# ATtiny1617 register map
Vendor: Atmel; File version: 1.0
CPU: other r0p0, little endian, no MPU, no FPU, 4 interrupt priority bits
Registers are 8-bit, read-write, reset 0x0 unless marked. A register's access mark holds for its fields unless they carry their own. Offsets are from the block's base; lines under a group give offsets from that group; [hi:lo] are bit positions; {n}, {i} and the like mark numbered series; 'fields as' and 'values as' point back to an identical list; <NAME> marks a mode.

## Memory map
0x00800000 VPORTA size 0x4 — Virtual Ports
0x00800004 VPORTB size 0x4 — Virtual Ports
0x00800008 VPORTC size 0x4 — Virtual Ports
0x0080001C GPIO size 0x4 — General Purpose IO
0x00800034 CPU blocks up to offset 0xB
0x00800040 RSTCTRL size 0x2 — Reset controller
0x00800050 SLPCTRL size 0x1 — Sleep Controller
0x00800060 CLKCTRL blocks up to offset 0x1D — Clock controller
0x00800080 BOD blocks up to offset 0xC — Bod interface
0x008000A0 VREF size 0x4 — Voltage reference
0x00800100 WDT size 0x2 — Watch-Dog Timer
0x00800110 CPUINT size 0x4 — Interrupt Controller
0x00800120 CRCSCAN size 0x3
0x00800140 RTC blocks up to offset 0x16 — Real-Time Counter
0x00800180 EVSYS blocks up to offset 0x24 — Event System
0x008001C0 CCL blocks up to offset 0xD — Configurable Custom Logic
0x00800200 PORTMUX size 0x4 — Port Multiplexer
0x00800400 PORTA blocks up to offset 0x18 — I/O Ports
0x00800420 PORTB blocks up to offset 0x18 — I/O Ports
0x00800440 PORTC blocks up to offset 0x18 — I/O Ports
0x00800600 ADC0 blocks up to offset 0x17 — Analog to Digital Converter
0x00800640 ADC1 blocks up to offset 0x17 — Analog to Digital Converter
0x00800680 AC0 blocks up to offset 0x8 — Analog Comparator
0x00800688 AC1 blocks up to offset 0x8 — Analog Comparator
0x00800690 AC2 blocks up to offset 0x8 — Analog Comparator
0x008006A0 DAC0 size 0x2 — Digital to Analog Converter
0x008006A8 DAC1 size 0x2 — Digital to Analog Converter
0x008006B0 DAC2 size 0x2 — Digital to Analog Converter
0x00800800 USART0 blocks up to offset 0xF — Universal Synchronous and Asynchronous Receiver and Transmitter
0x00800810 TWI0 blocks up to offset 0xF — Two-Wire Interface
0x00800820 SPI0 size 0x5 — Serial Peripheral Interface
0x00800A00 TCA0 blocks up to offset 0x3E — 16-bit Timer/Counter Type A
0x00800A40 TCB0 blocks up to offset 0xE — 16-bit Timer Type B
0x00800A50 TCB1 blocks up to offset 0xE — 16-bit Timer Type B
0x00800A80 TCD0 blocks up to offset 0x30 — Timer Counter D
0x00800F01 SYSCFG size 0x2 — System Configuration Registers
0x00801000 NVMCTRL blocks up to offset 0xA — Non-volatile Memory Controller
0x00801100 SIGROW blocks up to offset 0x26 — Signature row
0x00801280 FUSE blocks up to offset 0x9 — Fuses
0x0080128A LOCKBIT size 0x1
0x00801300 USERROW size 0x20

## Interrupts
1 CRCSCAN_NMI (CPU)
2 BOD_VLM (CPU)
3 PORTA_PORT (CPU)
4 PORTB_PORT (CPU)
5 PORTC_PORT (CPU)
6 RTC_CNT (CPU)
7 RTC_PIT (CPU)
8 TCA0_LUNF_OVF (CPU)
9 TCA0_HUNF (CPU)
10 TCA0_CMP0_LCMP0 (CPU)
11 TCA0_CMP1_LCMP1 (CPU)
12 TCA0_CMP2_LCMP2 (CPU)
13 TCB0_INT (CPU)
14 TCB1_INT (CPU)
15 TCD0_OVF (CPU)
16 TCD0_TRIG (CPU)
17 AC0_AC (CPU)
18 AC1_AC (CPU)
19 AC2_AC (CPU)
20 ADC0_RESRDY (CPU)
21 ADC0_WCOMP (CPU)
22 ADC1_RESRDY (CPU)
23 ADC1_WCOMP (CPU)
24 TWI0_TWIS (CPU)
25 TWI0_TWIM (CPU)
26 SPI0_INT (CPU)
27 USART0_RXC (CPU)
28 USART0_DRE (CPU)
29 USART0_TXC (CPU)
30 NVMCTRL_EE (CPU)

## AC0 — Analog Comparator
Base 0x00800680
Same registers: AC1 0x00800688, AC2 0x00800690
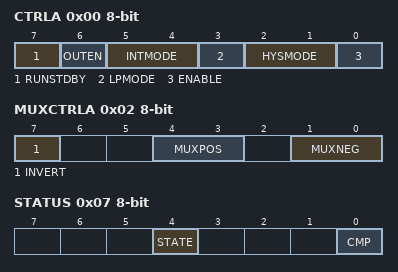
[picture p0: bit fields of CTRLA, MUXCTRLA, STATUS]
0x00 CTRLA — Control A
  [7] RUNSTDBY — Run in Standby Mode
  [6] OUTEN — Output Buffer Enable
  [5:4] INTMODE — Interrupt Mode
    0=BOTHEDGE (Any Edge); 2=NEGEDGE (Negative Edge); 3=POSEDGE (Positive Edge)
  [3] LPMODE — Low Power Mode
    0=DIS (Low power mode disabled); 1=EN (Low power mode enabled)
  [2:1] HYSMODE — Hysteresis Mode
    0=OFF (No hysteresis); 1=10mV hysteresis; 2=25mV hysteresis; 3=50mV hysteresis
  [0] ENABLE
0x02 MUXCTRLA — Mux Control A
  [7] INVERT — Invert AC Output
  [4:3] MUXPOS — Positive Input MUX Selection
    {v}=PIN{v} (Positive Pin {v}) (v=0..3)
  [1:0] MUXNEG — Negative Input MUX Selection
    0=PIN0 (Negative Pin 0); 1=PIN1 (Negative Pin 1); 2=VREF (Voltage Reference); 3=DAC (DAC output)
0x06 INTCTRL — Interrupt Control
  [0] CMP — Analog Comparator 0 Interrupt Enable
0x07 STATUS
  [4] STATE ro — Analog Comparator State
  [0] CMP — Analog Comparator Interrupt Flag
